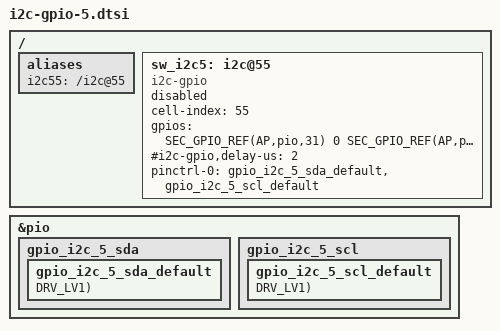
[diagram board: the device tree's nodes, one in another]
&pio {
       gpio_i2c_5_sda {
               gpio_i2c_5_sda_default: gpio_i2c_5_sda_default {
                       GPIO_CONFIG_PUD_DRV(AP,pio,31, FUNC_INPUT, PULL_NONE, DRV_LV1);
               };
       };
};

&pio {
       gpio_i2c_5_scl {
               gpio_i2c_5_scl_default: gpio_i2c_5_scl_default {
                       GPIO_CONFIG_PUD_DRV(AP,pio,30, FUNC_INPUT, PULL_NONE, DRV_LV1);
               };
       };
};

/ {
	fragment@model {
		target-path = "/";
	        __overlay__ {
			aliases {
				  i2c55 = "/i2c@55";
			};
			/* Software I2C */
			sw_i2c5: i2c@55 {
				cell-index = <55>;
				compatible = "i2c-gpio";
				gpios = <
					SEC_GPIO_REF(AP,pio,31) 0 /* SDA */
					SEC_GPIO_REF(AP,pio,30) 0 /* SCL */
					>;
				#i2c-gpio,delay-us = <2>;
				#address-cells = <1>;
				#size-cells = <0>;

				pinctrl-names = "default";
				pinctrl-0 = <
					&gpio_i2c_5_sda_default
					&gpio_i2c_5_scl_default
					>;

				status = "disabled";
			};
		};
	};
};

